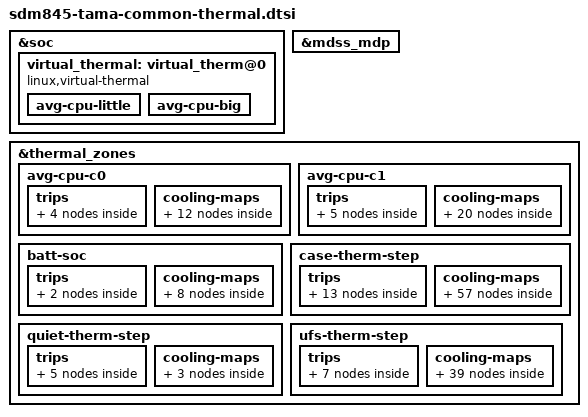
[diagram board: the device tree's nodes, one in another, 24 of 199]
/* arch/arm64/boot/dmsm8998-tama-common-thermal.dtsi
 *
 * This program is free software; you can redistribute it and/or modify
 * it under the terms of the GNU General Public License version 2 and
 * only version 2 as published by the Free Software Foundation.
 *
 * This program is distributed in the hope that it will be useful,
 * but WITHOUT ANY WARRANTY; without even the implied warranty of
 * MERCHANTABILITY or FITNESS FOR A PARTICULAR PURPOSE.  See the
 * GNU General Public License for more details.
 */
/*
 * Copyright (C) 2018 AngeloGioacchino Del Regno <kholk11@gmail.com>
 *
 * This program is free software; you can redistribute it and/or modify
 * it under the terms of the GNU General Public License version 2, as
 * published by the Free Software Foundation.
 */


&soc {
	virtual_thermal: virtual_therm@0 {
		compatible = "linux,virtual-thermal";
		status = "ok";
	};
};

&mdss_mdp {
	/* Backlight cooling device */
	#cooling-cells = <2>;
};

&virtual_thermal {
	avg-cpu-little {
		virt-zone-name = "avg-cpu-c0";
		thermal-sensor-names = "cpu0-silver-usr", "cpu1-silver-usr",
				  "cpu2-silver-usr", "cpu3-silver-usr",
				  "kryo-l3-0-usr";
		aggregation-logic = <0>; /* WEIGHTED_AVG */
	};
	avg-cpu-big {
		virt-zone-name = "avg-cpu-c1";
		thermal-sensor-names = "cpu0-gold-usr", "cpu2-gold-usr",
				  "cpu1-gold-usr", "cpu3-gold-usr",
				  "kryo-l3-1-usr";
		aggregation-logic = <0>; /* WEIGHTED_AVG */
	};
};

&thermal_zones {
	avg-cpu-c0 {
		polling-delay-passive = <500>;
		polling-delay = <750>;
		thermal-governor = "step_wise";
		trips {
			c0_crit: c0-crit {
				temperature = <90000>;
				hysteresis = <4000>;
				type = "critical";
			};

			c0_hot: c0-hot {
				temperature = <83000>;
				hysteresis = <4000>;
				type = "hot";
			};

			c0_trip1: c0-trip1 {
				temperature = <78000>;
				hysteresis = <3000>;
				type = "passive";
				
			};

			c0_trip2: c0-trip2 {
				temperature = <75000>;
				hysteresis = <4000>;
				type = "passive";
				
			};
		};

		cooling-maps {
			/* Throttle from FMAX to 748.8MHz */
			cpu0_hot_cdev {
				trip = <&c0_hot>;
				cooling-device =
					<&CPU0 THERMAL_NO_LIMIT
						(THERMAL_MAX_LIMIT-5)>;
			};
			cpu1_hot_cdev {
				trip = <&c0_hot>;
				cooling-device =
					<&CPU1 THERMAL_NO_LIMIT
						(THERMAL_MAX_LIMIT-5)>;
			};
			cpu2_hot_cdev {
				trip = <&c0_hot>;
				cooling-device =
					<&CPU2 THERMAL_NO_LIMIT
						(THERMAL_MAX_LIMIT-5)>;
			};
			cpu3_hot_cdev {
				trip = <&c0_hot>;
				cooling-device =
					<&CPU3 THERMAL_NO_LIMIT
						(THERMAL_MAX_LIMIT-5)>;
			};
			/* Throttle from FMAX to 1132.8MHz */
			cpu0_cdev1 {
				trip = <&c0_trip1>;
				cooling-device =
					<&CPU0 THERMAL_NO_LIMIT
						(THERMAL_MAX_LIMIT-10)>;
			};
			cpu1_cdev1 {
				trip = <&c0_trip1>;
				cooling-device =
					<&CPU1 THERMAL_NO_LIMIT
						(THERMAL_MAX_LIMIT-10)>;
			};
			cpu2_cdev1 {
				trip = <&c0_trip1>;
				cooling-device =
					<&CPU2 THERMAL_NO_LIMIT
						(THERMAL_MAX_LIMIT-10)>;
			};
			cpu3_cdev1 {
				trip = <&c0_trip1>;
				cooling-device =
					<&CPU3 THERMAL_NO_LIMIT
						(THERMAL_MAX_LIMIT-10)>;
			};


			/* Throttle from FMAX to 1612.8MHz */
			cpu0_cdev2 {
				trip = <&c0_trip2>;
				cooling-device =
					<&CPU0 THERMAL_NO_LIMIT
						(THERMAL_MAX_LIMIT-15)>;
			};
			cpu1_cdev2 {
				trip = <&c0_trip2>;
				cooling-device =
					<&CPU1 THERMAL_NO_LIMIT
						(THERMAL_MAX_LIMIT-15)>;
			};
			cpu2_cdev2 {
				trip = <&c0_trip2>;
				cooling-device =
					<&CPU2 THERMAL_NO_LIMIT
						(THERMAL_MAX_LIMIT-15)>;
			};
			cpu3_cdev2 {
				trip = <&c0_trip2>;
				cooling-device =
					<&CPU3 THERMAL_NO_LIMIT
						(THERMAL_MAX_LIMIT-15)>;
			};
		};
	};

	avg-cpu-c1 {
		polling-delay-passive = <300>;
		polling-delay = <500>;
		thermal-governor = "step_wise";
		trips {
			c1_hot: c1-hot {
				temperature = <86100>;
				hysteresis = <4000>;
				type = "hot";
			};

			c1_trip0: c1-trip0 {
				temperature = <82100>;
				hysteresis = <3000>;
				type = "passive";
			};

			c1_trip1: c1-trip1 {
				temperature = <77200>;
				hysteresis = <3000>;
				type = "passive";
				
			};

			c1_trip2: c1-trip2 {
				temperature = <76300>;
				hysteresis = <3000>;
				type = "passive";
				
			};

			c1_trip3: c1-trip3 {
				temperature = <70000>;
				hysteresis = <3000>;
				type = "passive";
			};
		};

		cooling-maps {
			/* Temperature is critical: Shut down c1 */
			cpu4_crit_cdev {
				trip = <&c1_hot>;
				cooling-device =
					<&CPU4 THERMAL_MAX_LIMIT
						THERMAL_MAX_LIMIT>;
			};
			cpu5_crit_cdev {
				trip = <&c1_hot>;
				cooling-device =
					<&CPU5 THERMAL_MAX_LIMIT
						THERMAL_MAX_LIMIT>;
			};
			cpu6_crit_cdev {
				trip = <&c1_hot>;
				cooling-device =
					<&CPU6 THERMAL_MAX_LIMIT
						THERMAL_MAX_LIMIT>;
			};
			cpu7_crit_cdev {
				trip = <&c1_hot>;
				cooling-device =
					<&CPU7 THERMAL_MAX_LIMIT
						THERMAL_MAX_LIMIT>;
			};

			/* Throttle from FMAX to 1536MHz */
			cpu4_cdev4 {
				trip = <&c1_trip0>;
				cooling-device =
					<&CPU4 THERMAL_NO_LIMIT
						(THERMAL_MAX_LIMIT-8)>;
			};
			cpu5_cdev4 {
				trip = <&c1_trip0>;
				cooling-device =
					<&CPU5 THERMAL_NO_LIMIT
						(THERMAL_MAX_LIMIT-8)>;
			};
			cpu6_cdev4 {
				trip = <&c1_trip0>;
				cooling-device =
					<&CPU6 THERMAL_NO_LIMIT
						(THERMAL_MAX_LIMIT-8)>;
			};
			cpu7_cdev4 {
				trip = <&c1_trip0>;
				cooling-device =
					<&CPU7 THERMAL_NO_LIMIT
						(THERMAL_MAX_LIMIT-8)>;
			};

			/* Throttle from FMAX to 2169.6MHz */
			cpu4_cdev5 {
				trip = <&c1_trip1>;
				cooling-device =
					<&CPU4 THERMAL_NO_LIMIT
						(THERMAL_MAX_LIMIT-16)>;
			};
			cpu5_cdev5 {
				trip = <&c1_trip1>;
				cooling-device =
					<&CPU5 THERMAL_NO_LIMIT
						(THERMAL_MAX_LIMIT-16)>;
			};
			cpu6_cdev5 {
				trip = <&c1_trip1>;
				cooling-device =
					<&CPU6 THERMAL_NO_LIMIT
						(THERMAL_MAX_LIMIT-16)>;
			};
			cpu7_cdev5 {
				trip = <&c1_trip1>;
				cooling-device =
					<&CPU7 THERMAL_NO_LIMIT
						(THERMAL_MAX_LIMIT-16)>;
			};

			/* Throttle from FMAX to 2707.2MHz */
			cpu4_cdev6 {
				trip = <&c1_trip2>;
				cooling-device =
					<&CPU4 THERMAL_NO_LIMIT
						(THERMAL_MAX_LIMIT-23)>;
			};
			cpu5_cdev6 {
				trip = <&c1_trip2>;
				cooling-device =
					<&CPU5 THERMAL_NO_LIMIT
						(THERMAL_MAX_LIMIT-23)>;
			};
			cpu6_cdev6 {
				trip = <&c1_trip2>;
				cooling-device =
					<&CPU6 THERMAL_NO_LIMIT
						(THERMAL_MAX_LIMIT-23)>;
			};
			cpu7_cdev6 {
				trip = <&c1_trip2>;
				cooling-device =
					<&CPU7 THERMAL_NO_LIMIT
						(THERMAL_MAX_LIMIT-23)>;
			};

			/* Disallow TURBO frequency */
			cpu4_cdev7 {
				trip = <&c1_trip3>;
				cooling-device =
					<&CPU4 THERMAL_NO_LIMIT 1>;
			};
			cpu5_cdev7 {
				trip = <&c1_trip3>;
				cooling-device =
					<&CPU5 THERMAL_NO_LIMIT 1>;
			};
			cpu6_cdev7 {
				trip = <&c1_trip3>;
				cooling-device =
					<&CPU6 THERMAL_NO_LIMIT 1>;
			};
			cpu7_cdev7 {
				trip = <&c1_trip3>;
				cooling-device =
					<&CPU7 THERMAL_NO_LIMIT 1>;
			};
		};
	};

	batt-soc {
		polling-delay-passive = <1000>;
		polling-delay = <0>;
		thermal-governor = "low_limits_cap";
		thermal-sensors = <&bcl_sensor 5>;
		tracks-low;

		trips {
			crit_low_soc: crit-low-soc {
				temperature = <7>;
				hysteresis = <0>;
				type = "passive";
			};
			lo_soc: low-soc {
				temperature = <10>;
				hysteresis = <0>;
				type = "passive";
			};
		};

		cooling-maps {
			/* Throttle C0 from FMAX to 1420.8MHz */
			crit_soc_cpu0 {
				trip = <&crit_low_soc>;
				cooling-device =
					<&CPU0 THERMAL_NO_LIMIT
						(THERMAL_MAX_LIMIT-14)>;
			};
			crit_soc_cpu1 {
				trip = <&crit_low_soc>;
				cooling-device =
					<&CPU1 THERMAL_NO_LIMIT
						(THERMAL_MAX_LIMIT-14)>;
			};
			crit_soc_cpu2 {
				trip = <&crit_low_soc>;
				cooling-device =
					<&CPU2 THERMAL_NO_LIMIT
						(THERMAL_MAX_LIMIT-14)>;
			};
			crit_soc_cpu3 {
				trip = <&crit_low_soc>;
				cooling-device =
					<&CPU3 THERMAL_NO_LIMIT
						(THERMAL_MAX_LIMIT-14)>;
			};

			/* Shut down C1 */
			soc_cpu4 {
				trip = <&lo_soc>;
				cooling-device =
					<&CPU4 THERMAL_MAX_LIMIT
						THERMAL_MAX_LIMIT>;
			};
			soc_cpu5 {
				trip = <&lo_soc>;
				cooling-device =
					<&CPU5 THERMAL_MAX_LIMIT
						THERMAL_MAX_LIMIT>;
			};
			soc_cpu6 {
				trip = <&lo_soc>;
				cooling-device =
					<&CPU6 THERMAL_MAX_LIMIT
						THERMAL_MAX_LIMIT>;
			};
			soc_cpu7 {
				trip = <&lo_soc>;
				cooling-device =
					<&CPU7 THERMAL_MAX_LIMIT
						THERMAL_MAX_LIMIT>;
			};
		};
	};

	case-therm-step {
		polling-delay-passive = <2000>;
		polling-delay = <0>;
		thermal-sensors = <&pm8998_adc_tm 0x4d>;
		thermal-governor = "step_wise";

		trips {
			skin_critical: skin-crit {
				temperature = <73500>;
				hysteresis = <2000>;
				type = "critical";
			};

			cpu_ct_trip0: cpu-ct-trip0 {
				temperature = <63000>;
				hysteresis = <3000>;
				type = "passive";
			};
			cpu_ct_trip1: cpu-ct-trip1 {
				temperature = <55700>;
				hysteresis = <1000>;
				type = "passive";
			};
			cpu_ct_trip2: cpu-ct-trip2 {
				temperature = <54700>;
				hysteresis = <1200>;
				type = "passive";
			};
			cpu_ct_trip3: cpu-ct-trip3 {
				temperature = <52500>;
				hysteresis = <1100>;
				type = "passive";
			};
			cpu_ct_trip4: cpu-ct-trip4 {
				temperature = <51400>;
				hysteresis = <1200>;
				type = "passive";
			};
			cpu_ct_trip5: cpu-ct-trip5 {
				temperature = <50200>;
				hysteresis = <300>;
				type = "passive";
			};
			cpu_ct_trip6: cpu-ct-trip6 {
				temperature = <48600>;
				hysteresis = <1200>;
				type = "passive";
			};
			cpu_ct_trip7: cpu-ct-trip7 {
				temperature = <47700>;
				hysteresis = <2700>;
				type = "passive";
			};

			charger_trip0: cpu-ct-trip8 {
				temperature = <45000>;
				hysteresis = <3000>;
				type = "passive";
			};

			modem_case_trip0: modem-trip0 {
				temperature = <47000>;
				hysteresis = <2000>;
				type = "passive";
			};
			modem_case_trip1: modem-trip1 {
				temperature = <51000>;
				hysteresis = <3000>;
				type = "passive";
			};
			modem_case_trip2: modem-trip2 {
				temperature = <55000>;
				hysteresis = <4000>;
				type = "passive";
			};
		};

		cooling-maps {
			/* Throttle from FMAX to 576MHz */
			skin0_cpu0 {
				trip = <&cpu_ct_trip0>;
				cooling-device = <&CPU0 THERMAL_NO_LIMIT
							(THERMAL_MAX_LIMIT-4)>;
			};
			skin0_cpu1 {
				trip = <&cpu_ct_trip0>;
				cooling-device = <&CPU1 THERMAL_NO_LIMIT
							(THERMAL_MAX_LIMIT-4)>;
			};
			skin0_cpu2 {
				trip = <&cpu_ct_trip0>;
				cooling-device = <&CPU2 THERMAL_NO_LIMIT
							(THERMAL_MAX_LIMIT-4)>;
			};
			skin0_cpu3 {
				trip = <&cpu_ct_trip0>;
				cooling-device = <&CPU3 THERMAL_NO_LIMIT
							(THERMAL_MAX_LIMIT-4)>;
			};
			/* Reaching critical: shutdown C1 */
			skin0_cpu4 {
				trip = <&cpu_ct_trip0>;
				cooling-device = <&CPU4 THERMAL_NO_LIMIT
							THERMAL_MAX_LIMIT>;
			};
			skin0_cpu5 {
				trip = <&cpu_ct_trip0>;
				cooling-device = <&CPU5 THERMAL_NO_LIMIT
							THERMAL_MAX_LIMIT>;
			};
			skin0_cpu6 {
				trip = <&cpu_ct_trip0>;
				cooling-device = <&CPU6 THERMAL_NO_LIMIT
							THERMAL_MAX_LIMIT>;
			};
			skin0_cpu7 {
				trip = <&cpu_ct_trip0>;
				cooling-device = <&CPU7 THERMAL_NO_LIMIT
							THERMAL_MAX_LIMIT>;
			};

			/* Throttle from FMAX to 1056-902.4MHz */
			skin1_cpu0 {
				trip = <&cpu_ct_trip1>;
				cooling-device = <&CPU0 THERMAL_NO_LIMIT
							(THERMAL_MAX_LIMIT-8)>;
			};
			skin1_cpu1 {
				trip = <&cpu_ct_trip1>;
				cooling-device = <&CPU1 THERMAL_NO_LIMIT
							(THERMAL_MAX_LIMIT-8)>;
			};
			skin1_cpu2 {
				trip = <&cpu_ct_trip1>;
				cooling-device = <&CPU2 THERMAL_NO_LIMIT
							(THERMAL_MAX_LIMIT-8)>;
			};
			skin1_cpu3 {
				trip = <&cpu_ct_trip1>;
				cooling-device = <&CPU3 THERMAL_NO_LIMIT
							(THERMAL_MAX_LIMIT-8)>;
			};
			skin1_cpu4 {
				trip = <&cpu_ct_trip1>;
				cooling-device = <&CPU4 THERMAL_NO_LIMIT
							(THERMAL_MAX_LIMIT-4)>;
			};
			skin1_cpu5 {
				trip = <&cpu_ct_trip1>;
				cooling-device = <&CPU5 THERMAL_NO_LIMIT
							(THERMAL_MAX_LIMIT-4)>;
			};
			skin1_cpu6 {
				trip = <&cpu_ct_trip1>;
				cooling-device = <&CPU6 THERMAL_NO_LIMIT
							(THERMAL_MAX_LIMIT-4)>;
			};
			skin1_cpu7 {
				trip = <&cpu_ct_trip1>;
				cooling-device = <&CPU7 THERMAL_NO_LIMIT
							(THERMAL_MAX_LIMIT-4)>;
			};

			/* Throttle from FMAX to 1689.6-1420.8MHz */
			skin2_cpu0 {
				trip = <&cpu_ct_trip2>;
				cooling-device = <&CPU0 THERMAL_NO_LIMIT
							(THERMAL_MAX_LIMIT-14)>;
			};
			skin2_cpu1 {
				trip = <&cpu_ct_trip2>;
				cooling-device = <&CPU1 THERMAL_NO_LIMIT
							(THERMAL_MAX_LIMIT-14)>;
			};
			skin2_cpu2 {
				trip = <&cpu_ct_trip2>;
				cooling-device = <&CPU2 THERMAL_NO_LIMIT
							(THERMAL_MAX_LIMIT-14)>;
			};
			skin2_cpu3 {
				trip = <&cpu_ct_trip2>;
				cooling-device = <&CPU3 THERMAL_NO_LIMIT
							(THERMAL_MAX_LIMIT-14)>;
			};
			skin2_cpu4 {
				trip = <&cpu_ct_trip2>;
				cooling-device = <&CPU4 THERMAL_NO_LIMIT
							(THERMAL_MAX_LIMIT-11)>;
			};
			skin2_cpu5 {
				trip = <&cpu_ct_trip2>;
				cooling-device = <&CPU5 THERMAL_NO_LIMIT
							(THERMAL_MAX_LIMIT-11)>;
			};
			skin2_cpu6 {
				trip = <&cpu_ct_trip2>;
				cooling-device = <&CPU6 THERMAL_NO_LIMIT
							(THERMAL_MAX_LIMIT-11)>;
			};
			skin2_cpu7 {
				trip = <&cpu_ct_trip2>;
				cooling-device = <&CPU7 THERMAL_NO_LIMIT
							(THERMAL_MAX_LIMIT-11)>;
			};

			/* Throttle from FMAX to 1843.2-1516.8MHz */
			skin3_cpu0 {
				trip = <&cpu_ct_trip3>;
				cooling-device = <&CPU0 THERMAL_NO_LIMIT
							(THERMAL_MAX_LIMIT-15)>;
			};
			skin3_cpu1 {
				trip = <&cpu_ct_trip3>;
				cooling-device = <&CPU1 THERMAL_NO_LIMIT
							(THERMAL_MAX_LIMIT-15)>;
			};
			skin3_cpu2 {
				trip = <&cpu_ct_trip3>;
				cooling-device = <&CPU2 THERMAL_NO_LIMIT
							(THERMAL_MAX_LIMIT-15)>;
			};
			skin3_cpu3 {
				trip = <&cpu_ct_trip3>;
				cooling-device = <&CPU3 THERMAL_NO_LIMIT
							(THERMAL_MAX_LIMIT-15)>;
			};
			skin3_cpu4 {
				trip = <&cpu_ct_trip3>;
				cooling-device = <&CPU4 THERMAL_NO_LIMIT
							(THERMAL_MAX_LIMIT-13)>;
			};
			skin3_cpu5 {
				trip = <&cpu_ct_trip3>;
				cooling-device = <&CPU5 THERMAL_NO_LIMIT
							(THERMAL_MAX_LIMIT-13)>;
			};
			skin3_cpu6 {
				trip = <&cpu_ct_trip3>;
				cooling-device = <&CPU6 THERMAL_NO_LIMIT
							(THERMAL_MAX_LIMIT-13)>;
			};
			skin3_cpu7 {
				trip = <&cpu_ct_trip3>;
				cooling-device = <&CPU7 THERMAL_NO_LIMIT
							(THERMAL_MAX_LIMIT-13)>;
			};


			/* Throttle C1 only from FMAX to 2246.4MHz */
			skin4_cpu4 {
				trip = <&cpu_ct_trip4>;
				cooling-device = <&CPU4 THERMAL_NO_LIMIT
							(THERMAL_MAX_LIMIT-18)>;
			};
			skin4_cpu5 {
				trip = <&cpu_ct_trip4>;
				cooling-device = <&CPU5 THERMAL_NO_LIMIT
							(THERMAL_MAX_LIMIT-18)>;
			};
			skin4_cpu6 {
				trip = <&cpu_ct_trip4>;
				cooling-device = <&CPU6 THERMAL_NO_LIMIT
							(THERMAL_MAX_LIMIT-18)>;
			};
			skin4_cpu7 {
				trip = <&cpu_ct_trip4>;
				cooling-device = <&CPU7 THERMAL_NO_LIMIT
							(THERMAL_MAX_LIMIT-18)>;
			};

			/* Throttle C1 only from FMAX to 2476.8MHz */
			skin5_cpu4 {
				trip = <&cpu_ct_trip5>;
				cooling-device = <&CPU4 THERMAL_NO_LIMIT
							(THERMAL_MAX_LIMIT-21)>;
			};
			skin5_cpu5 {
				trip = <&cpu_ct_trip5>;
				cooling-device = <&CPU5 THERMAL_NO_LIMIT
							(THERMAL_MAX_LIMIT-21)>;
			};
			skin5_cpu6 {
				trip = <&cpu_ct_trip5>;
				cooling-device = <&CPU6 THERMAL_NO_LIMIT
							(THERMAL_MAX_LIMIT-21)>;
			};
			skin5_cpu7 {
				trip = <&cpu_ct_trip5>;
				cooling-device = <&CPU7 THERMAL_NO_LIMIT
							(THERMAL_MAX_LIMIT-21)>;
			};

			/* Throttle C1 only from FMAX to 2649.6MHz */
			skin6_cpu4 {
				trip = <&cpu_ct_trip6>;
				cooling-device = <&CPU4 THERMAL_NO_LIMIT
							(THERMAL_MAX_LIMIT-23)>;
			};
			skin6_cpu5 {
				trip = <&cpu_ct_trip6>;
				cooling-device = <&CPU5 THERMAL_NO_LIMIT
							(THERMAL_MAX_LIMIT-23)>;
			};
			skin6_cpu6 {
				trip = <&cpu_ct_trip6>;
				cooling-device = <&CPU6 THERMAL_NO_LIMIT
							(THERMAL_MAX_LIMIT-23)>;
			};
			skin6_cpu7 {
				trip = <&cpu_ct_trip6>;
				cooling-device = <&CPU7 THERMAL_NO_LIMIT
							(THERMAL_MAX_LIMIT-23)>;
			};

			/* Throttle from FMAX to 210MHz */
			skin0_gpu {
				trip = <&cpu_ct_trip1>;
				cooling-device = <&msm_gpu THERMAL_NO_LIMIT
							   (THERMAL_MAX_LIMIT-1)>;
			};

			/* Battery charging current limit */
			charger_lvl1 {
				trip = <&cpu_ct_trip0>;
				cooling-device = <&pmi8998_charger 13 13>;
			};
			charger_lvl2 {
				trip = <&cpu_ct_trip1>;
				cooling-device = <&pmi8998_charger 12 12>;
			};
			charger_lvl3 {
				trip = <&cpu_ct_trip2>;
				cooling-device = <&pmi8998_charger 11 11>;
			};
			charger_lvl4 {
				trip = <&cpu_ct_trip3>;
				cooling-device = <&pmi8998_charger 10 10>;
			};
			charger_lvl5 {
				trip = <&cpu_ct_trip4>;
				cooling-device = <&pmi8998_charger 9 9>;
			};
			charger_lvl6 {
				trip = <&cpu_ct_trip5>;
				cooling-device = <&pmi8998_charger 8 8>;
			};
			charger_lvl7 {
				trip = <&cpu_ct_trip6>;
				cooling-device = <&pmi8998_charger 5 5>;
			};
			charger_lvl8 {
				trip = <&cpu_ct_trip7>;
				cooling-device = <&pmi8998_charger 2 2>;
			};

			/* Modem PA power limit */
			modem_lvl1 {
				trip = <&modem_case_trip1>;
				cooling-device = <&modem_pa 1 1>;
			};
			modem_lvl2 {
				trip = <&modem_case_trip2>;
				cooling-device = <&modem_pa 2 2>;
			};

			/* Modem proc limit */
			modem_proc_lvl1 {
				trip = <&modem_case_trip0>;
				cooling-device = <&modem_proc 1 1>;
			};
			modem_proc_lvl2 {
				trip = <&modem_case_trip2>;
				cooling-device = <&modem_proc 3 3>;
			};
		};
	};

	/* Backlight protection */
	quiet-therm-step {
		polling-delay-passive = <1000>;
		polling-delay = <0>;
		thermal-sensors = <&pm8998_adc_tm 0x51>;
		thermal-governor = "step_wise";

		trips {
			backlight_critical: backlight-crit {
				temperature = <55000>;
				hysteresis = <1000>;
				type = "critical";
			};

			backlight_trip_hot: backlight-hot {
				temperature = <50000>;
				hysteresis = <500>;
				type = "passive";
			};

			backlight_trip0: backlight-trip0 {
				temperature = <49500>;
				hysteresis = <600>;
				type = "passive";
			};
			backlight_trip1: backlight-trip1 {
				temperature = <48900>;
				hysteresis = <1200>;
				type = "passive";
			};
			backlight_trip2: backlight-trip2 {
				temperature = <47600>;
				hysteresis = <500>;
				type = "passive";
			};
		};

		cooling-maps {
			/* Backlight limits */
			bl_lvl1 {
				trip = <&backlight_trip0>;
				cooling-device = <&mdss_mdp 1 206>;
			};
			bl_lvl2 {
				trip = <&backlight_trip1>;
				cooling-device = <&mdss_mdp 1 214>;
			};
			bl_lvl3 {
				trip = <&backlight_trip2>;
				cooling-device = <&mdss_mdp 1 234>;
			};
		};
	};

	ufs-therm-step {
		polling-delay-passive = <1000>;
		polling-delay = <0>;
		thermal-sensors = <&pm8998_adc_tm 0x4e>;
		thermal-governor = "step_wise";

		trips {
			ufs_critical: ufs-crit {
				temperature = <78000>;
				hysteresis = <1000>;
				type = "critical";
			};

			ufs_trip_hot: ufs-hot {
				temperature = <69100>;
				hysteresis = <4000>;
				type = "passive";
			};

			ufs_trip0: ufs-trip0 {
				temperature = <64500>;
				hysteresis = <4000>;
				type = "passive";
			};
			ufs_trip1: ufs-trip1 {
				temperature = <55100>;
				hysteresis = <1000>;
				type = "passive";
			};
			ufs_trip2: ufs-trip2 {
				temperature = <54300>;
				hysteresis = <1200>;
				type = "passive";
			};
			ufs_trip3: ufs-trip3 {
				temperature = <52900>;
				hysteresis = <1100>;
				type = "passive";
			};
			ufs_trip4: ufs-trip4 {
				temperature = <50800>;
				hysteresis = <1200>;
				type = "passive";
			};
		};

		cooling-maps {
			/* Throttle from FMAX to 576MHz */
			ufs_mit_0_cpu0 {
				trip = <&ufs_trip0>;
				cooling-device = <&CPU0 THERMAL_NO_LIMIT
							(THERMAL_MAX_LIMIT-4)>;
			};
			ufs_mit_0_cpu1 {
				trip = <&ufs_trip0>;
				cooling-device = <&CPU1 THERMAL_NO_LIMIT
							(THERMAL_MAX_LIMIT-4)>;
			};
			ufs_mit_0_cpu2 {
				trip = <&ufs_trip0>;
				cooling-device = <&CPU2 THERMAL_NO_LIMIT
							(THERMAL_MAX_LIMIT-4)>;
			};
			ufs_mit_0_cpu3 {
				trip = <&ufs_trip0>;
				cooling-device = <&CPU3 THERMAL_NO_LIMIT
							(THERMAL_MAX_LIMIT-4)>;
			};
			/* Reaching critical: shutdown C1 */
			ufs_mit_0_cpu4 {
				trip = <&ufs_trip0>;
				cooling-device = <&CPU4 THERMAL_NO_LIMIT
							THERMAL_MAX_LIMIT>;
			};
			ufs_mit_0_cpu5 {
				trip = <&ufs_trip0>;
				cooling-device = <&CPU5 THERMAL_NO_LIMIT
							THERMAL_MAX_LIMIT>;
			};
			ufs_mit_0_cpu6 {
				trip = <&ufs_trip0>;
				cooling-device = <&CPU6 THERMAL_NO_LIMIT
							THERMAL_MAX_LIMIT>;
			};
			ufs_mit_0_cpu7 {
				trip = <&ufs_trip0>;
				cooling-device = <&CPU7 THERMAL_NO_LIMIT
							THERMAL_MAX_LIMIT>;
			};

			/* Throttle from FMAX to 1689.6-1420.8MHz */
			ufs_mit_1_cpu0 {
				trip = <&ufs_trip1>;
				cooling-device = <&CPU0 THERMAL_NO_LIMIT
							(THERMAL_MAX_LIMIT-14)>;
			};
			ufs_mit_1_cpu1 {
				trip = <&ufs_trip1>;
				cooling-device = <&CPU1 THERMAL_NO_LIMIT
							(THERMAL_MAX_LIMIT-14)>;
			};
			ufs_mit_1_cpu2 {
				trip = <&ufs_trip1>;
				cooling-device = <&CPU2 THERMAL_NO_LIMIT
							(THERMAL_MAX_LIMIT-14)>;
			};
			ufs_mit_1_cpu3 {
				trip = <&ufs_trip1>;
				cooling-device = <&CPU3 THERMAL_NO_LIMIT
							(THERMAL_MAX_LIMIT-14)>;
			};
			ufs_mit_1_cpu4 {
				trip = <&ufs_trip1>;
				cooling-device = <&CPU4 THERMAL_NO_LIMIT
							(THERMAL_MAX_LIMIT-11)>;
			};
			ufs_mit_1_cpu5 {
				trip = <&ufs_trip1>;
				cooling-device = <&CPU5 THERMAL_NO_LIMIT
							(THERMAL_MAX_LIMIT-11)>;
			};
			ufs_mit_1_cpu6 {
				trip = <&ufs_trip1>;
				cooling-device = <&CPU6 THERMAL_NO_LIMIT
							(THERMAL_MAX_LIMIT-11)>;
			};
			ufs_mit_1_cpu7 {
				trip = <&ufs_trip1>;
				cooling-device = <&CPU7 THERMAL_NO_LIMIT
							(THERMAL_MAX_LIMIT-11)>;
			};

			/* Throttle from FMAX to 1843.2-1516.8MHz */
			ufs_mit_2_cpu0 {
				trip = <&ufs_trip2>;
				cooling-device = <&CPU0 THERMAL_NO_LIMIT
							(THERMAL_MAX_LIMIT-15)>;
			};
			ufs_mit_2_cpu1 {
				trip = <&ufs_trip2>;
				cooling-device = <&CPU1 THERMAL_NO_LIMIT
							(THERMAL_MAX_LIMIT-15)>;
			};
			ufs_mit_2_cpu2 {
				trip = <&ufs_trip2>;
				cooling-device = <&CPU2 THERMAL_NO_LIMIT
							(THERMAL_MAX_LIMIT-15)>;
			};
			ufs_mit_2_cpu3 {
				trip = <&ufs_trip2>;
				cooling-device = <&CPU3 THERMAL_NO_LIMIT
							(THERMAL_MAX_LIMIT-15)>;
			};
			ufs_mit_2_cpu4 {
				trip = <&ufs_trip2>;
				cooling-device = <&CPU4 THERMAL_NO_LIMIT
							(THERMAL_MAX_LIMIT-13)>;
			};
			ufs_mit_2_cpu5 {
				trip = <&ufs_trip2>;
				cooling-device = <&CPU5 THERMAL_NO_LIMIT
							(THERMAL_MAX_LIMIT-13)>;
			};
			ufs_mit_2_cpu6 {
				trip = <&ufs_trip2>;
				cooling-device = <&CPU6 THERMAL_NO_LIMIT
							(THERMAL_MAX_LIMIT-13)>;
			};
			ufs_mit_2_cpu7 {
				trip = <&ufs_trip2>;
				cooling-device = <&CPU7 THERMAL_NO_LIMIT
							(THERMAL_MAX_LIMIT-13)>;
			};

			/* Throttle C1 only from FMAX to 2649.6MHz */
			ufs_mit_3_cpu4 {
				trip = <&ufs_trip3>;
				cooling-device = <&CPU4 THERMAL_NO_LIMIT
							(THERMAL_MAX_LIMIT-23)>;
			};
			ufs_mit_3_cpu5 {
				trip = <&ufs_trip3>;
				cooling-device = <&CPU5 THERMAL_NO_LIMIT
							(THERMAL_MAX_LIMIT-23)>;
			};
			ufs_mit_3_cpu6 {
				trip = <&ufs_trip3>;
				cooling-device = <&CPU6 THERMAL_NO_LIMIT
							(THERMAL_MAX_LIMIT-23)>;
			};
			ufs_mit_3_cpu7 {
				trip = <&ufs_trip3>;
				cooling-device = <&CPU7 THERMAL_NO_LIMIT
							(THERMAL_MAX_LIMIT-23)>;
			};


			/* Throttle C1 only from FMAX to 2784.8MHz */
			ufs_mit_4_cpu4 {
				trip = <&ufs_trip4>;
				cooling-device = <&CPU4 THERMAL_NO_LIMIT
							(THERMAL_MAX_LIMIT-24)>;
			};
			ufs_mit_4_cpu5 {
				trip = <&ufs_trip4>;
				cooling-device = <&CPU5 THERMAL_NO_LIMIT
							(THERMAL_MAX_LIMIT-24)>;
			};
			ufs_mit_4_cpu6 {
				trip = <&ufs_trip4>;
				cooling-device = <&CPU6 THERMAL_NO_LIMIT
							(THERMAL_MAX_LIMIT-24)>;
			};
			ufs_mit_4_cpu7 {
				trip = <&ufs_trip4>;
				cooling-device = <&CPU7 THERMAL_NO_LIMIT
							(THERMAL_MAX_LIMIT-24)>;
			};

			/* Battery charging current limit */
			charger_ufs_lvl1 {
				trip = <&ufs_trip0>;
				cooling-device = <&pmi8998_charger 13 13>;
			};
			charger_ufs_lvl2 {
				trip = <&ufs_trip1>;
				cooling-device = <&pmi8998_charger 12 12>;
			};
			charger_ufs_lvl3 {
				trip = <&ufs_trip2>;
				cooling-device = <&pmi8998_charger 11 11>;
			};
			charger_ufs_lvl4 {
				trip = <&ufs_trip3>;
				cooling-device = <&pmi8998_charger 10 10>;
			};
			charger_ufs_lvl5 {
				trip = <&ufs_trip4>;
				cooling-device = <&pmi8998_charger 9 9>;
			};

			/* Modem proc limit for UFS overheat */
			modem_proc_lvl1 {
				trip = <&ufs_trip0>;
				cooling-device = <&modem_proc 1 1>;
			};

			/* Modem PA power limit */
			modem_lvl1 {
				trip = <&ufs_trip_hot>;
				cooling-device = <&modem_pa 1 1>;
			};
		};
	};
};
